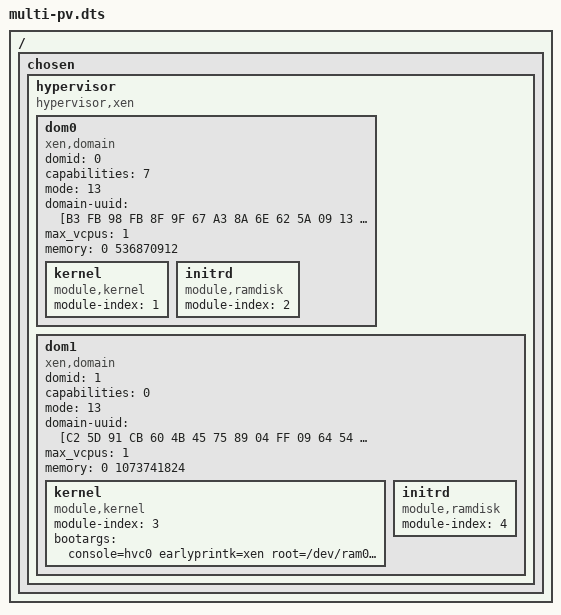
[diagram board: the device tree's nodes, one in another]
/dts-v1/;

/ {
	chosen {
		hypervisor {
			compatible = "hypervisor,xen", "xen,x86";

			dom0 {
				compatible = "xen,domain";

				domid = <0>;

				capabilities = <7>;
				mode = <13>;

				domain-uuid = [B3 FB 98 FB 8F 9F 67 A3 8A 6E 62 5A 09 13 F0 8C];

				max_vcpus = <1>;
				memory = <0 536870912>;

				kernel {
					compatible = "module,kernel", "module,index";
					module-index = <1>;
				};

				initrd {
					compatible = "module,ramdisk", "module,index";
					module-index = <2>;
				};
			};

			dom1 {
				compatible = "xen,domain";
				domid = <1>;
				capabilities = <0>;
				mode = <13>;
				domain-uuid = [C2 5D 91 CB 60 4B 45 75 89 04 FF 09 64 54 1A 74];
				max_vcpus = <1>;
				memory = <0 1073741824>;

				kernel {
					compatible = "module,kernel", "module,index";
					module-index = <3>;
					bootargs = "console=hvc0 earlyprintk=xen root=/dev/ram0 rw";
				};

				initrd {
					compatible = "module,ramdisk", "module,index";
					module-index = <4>;
				};
			};
		};
	};
};
